# StarFive VisionFive 2 v1.2A register map
File version: 0.1
Registers are 32-bit, read-write, reset 0x0 unless marked. A register's access mark holds for its fields unless they carry their own. Offsets are from the block's base; [hi:lo] are bit positions; {n}, {i} and the like mark numbered series; 'fields as' and 'values as' point back to an identical list.

## aon_pinctrl — From starfive,jh7110-aon-pinctrl, peripheral generator
Base 0x17020000
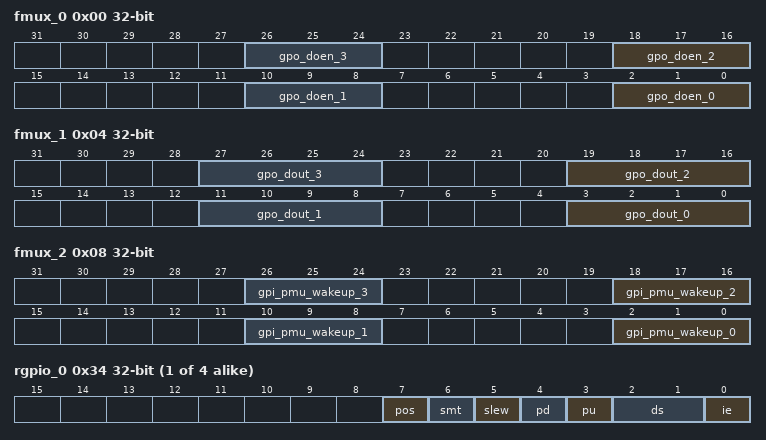
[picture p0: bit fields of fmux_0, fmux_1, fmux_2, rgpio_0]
0x00 fmux_0 — AON IOMUX CFG SAIF SYSCFG FMUX 0
  [8n+2:8n] gpo_doen_{n} (n=0..3) — The selected OEN signal for GPIO{n}. The register value indicates the selected GPIO (Output Enable) OEN index from GPIO OEN list 0-5. See Table 2-42: GPIO OEN List for AON_IOMUX for more information.
0x04 fmux_1 — AON IOMUX CFG SAIF SYSCFG FMUX 4
  [8n+3:8n] gpo_dout_{n} (n=0..3) — The selected OEN signal for GPIO{n}. The register value indicates the selected GPIO output signal list 0-9. See Table 2-42: GPIO OEN List for AON_IOMUX for more information.
0x08 fmux_2 — AON IOMUX CFG SAIF SYSCFG FMUX 8
  [8n+2:8n] gpi_pmu_wakeup_{n} (n=0..3) — The register value indicates the selected GPIO number + 2 (GPIO2-GPIO63, GPIO0 and GPIO1 are not available) for the input signal.
0x0C fmux_3 — AON IOMUX CFG SAIF SYSCFG FMUX 12
  [0] gpen_0 — Enable GPIO IRQ function.
0x10 ioirq_0 — AON IOMUX CFG SAIF SYSCFG IOIRQ 16
  [3:0] is — 1: Edge trigger, 0: Level trigger
0x14 ioirq_1 — AON IOMUX CFG SAIF SYSCFG IOIRQ 20
  [3:0] ic — 1: Do not clear the register, 0: Clear the register
0x18 ioirq_2 — AON IOMUX CFG SAIF SYSCFG IOIRQ 24
  [3:0] ibe — 1: Trigger on both edges, 0: Trigger on a single edge
0x1C ioirq_3 — AON IOMUX CFG SAIF SYSCFG IOIRQ 28
  [3:0] iev — 1: Positive/Low, 0: Negative/High
0x20 ioirq_4 — AON IOMUX CFG SAIF SYSCFG IOIRQ 32
  [3:0] ie — 1: Unmask, 0: Mask
0x24 ioirq_5 — AON IOMUX CFG SAIF SYSCFG IOIRQ 36
  [3:0] ris ro — Status of the edge trigger, can be cleared by writing gpioic.
0x28 ioirq_6 — AON IOMUX CFG SAIF SYSCFG IOIRQ 40
  [3:0] mis ro — The masked GPIO IRQ status.
0x2C ioirq_7 — AON IOMUX CFG SAIF SYSCFG IOIRQ 44
  [3:0] in_sync2 ro — Status of gpio_in after synchronization.
0x30 testen — AON IOMUX CFG SAIF SYSCFG 48
  [0] testen_pos — Power-on-Start (POS) enabler - 1: Enable active pull down for loss of core power, 0: Active pull-down capability disabled
{0x34+4i} rgpio_{i} (i=0..3) — AON IOMUX CFG SAIF SYSCFG {4i+52}
  [7] pos — Power-on-Start (POS) enabler - 1: Enable active pull down for loss of core power, 0: Active pull-down capability disabled
  [6] smt — Active high Schmitt (SMT) trigger selector - 0: No hysteresis, 1: Schmitt trigger ebabled
  [5] slew — Slew Rate Control - 0: Slow (Half frequency), 1: Fast
  [4] pd — Pull-Down (PD) settings - 1: Yes, 0: No
  [3] pu — Pull-Up (PU) settings - 1: Yes, 0: No
  [2:1] ds — Output Drive Strength (DS) - 00: The rated drive strength is 2 mA, 01: The rated drive strength is 4 mA, 10: The rated drive strength is 8 mA, 11: The rated drive strength is 12 mA
  [0] ie — Input Enable (IE) Controller - 1: Enable the receiver, 0: Disable the receiver
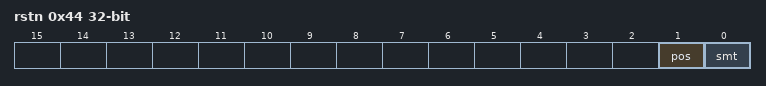
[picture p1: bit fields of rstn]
0x44 rstn — AON IOMUX CFG SAIF SYSCFG 68
  [1] pos — Power-on-Start (POS) enabler - 1: Enable active pull-down for loss of core power, 0: Active pull-down capability disabled
  [0] smt — Active high Schmitt (SMT) trigger selector - 0: No hysteresis, 1: Schmitt trigger enabled
0x4C rtc — AON IOMUX CFG SAIF SYSCFG 76
  [1:0] ds — Output Drive Strength (DS): * 00: The rated drive strength is 2 mA. * 01: The rated drive strength is 4 mA. * 10: The rated drive strength is 8 mA. * 11: The rated drive strength is 12 mA.
0x54 osc — AON IOMUX CFG SAIF SYSCFG 84
  fields as rtc
0x58 gmac0_mdc — AON IOMUX CFG SAIF SYSCFG 88
  [1:0] value
0x5C gmac0_mdio — AON IOMUX CFG SAIF SYSCFG 92
  [1:0] value
0x60 gmac0_rxd0 — AON IOMUX CFG SAIF SYSCFG 96
  [1:0] value — 0: GMAC0 IO voltage select 3.3V, 1: GMAC0 IO voltage select 2.5V, 2: GMAC0 IO voltage select 1.8V
{0x60+4i} gmac0_rxd{i} (i=1..3) — AON IOMUX CFG SAIF SYSCFG {4i+96}
  [1:0] value
0x70 gmac0_rxdv — AON IOMUX CFG SAIF SYSCFG 112
  [1:0] value
0x74 gmac0_rxc — AON IOMUX CFG SAIF SYSCFG 116
  [1:0] value
{0x78+4i} gmac0_txd{i} (i=0..3) — AON IOMUX CFG SAIF SYSCFG {4i+120}
  [1:0] value
0x88 gmac0_txen — AON IOMUX CFG SAIF SYSCFG 136
  [1:0] value
0x8C gmac0_txc — AON IOMUX CFG SAIF SYSCFG 140
  [1:0] value
0x90 gmac0_rxc_func_sel — AON IOMUX CFG SAIF SYSCFG 144
  [1:0] value — Function selector of GMAC0_RXC: * Function 0: u0_aon_crg_clk_gmac0_rgmii_rx, * Function 1: u0_aon_crg_clk_gmac0_rmii_ref, * Function 2: None, * Function 3: None
